# spc_me30 register map
Registers are access not given, no defined reset value unless marked. A register's access mark holds for its fields unless they carry their own. Offsets are from the block's base; lines under a group give offsets from that group; [hi:lo] are bit positions; {n}, {i} and the like mark numbered series; 'fields as' and 'values as' point back to an identical list; <NAME> marks a mode.

## Memory map
0x50090000 SPC size 0x1000 — Secure Privilege Controller.

## SPC — Secure Privilege Controller.
Base 0x50090000
0x00 CTRL 32-bit — SPC Secure Configuration Control Register.
  [0] LOCK — Write 1 to set, disables writes to security-related control registers in the SPC. Once set, the locked registers cannot be modified nor can this bit be cleared to 0 except through a reset.
0x08 RESP 32-bit — Security Violation Response Configuration Register.
  [0] VIOLCFG — This field configures the target response in case of a secuirty violation.
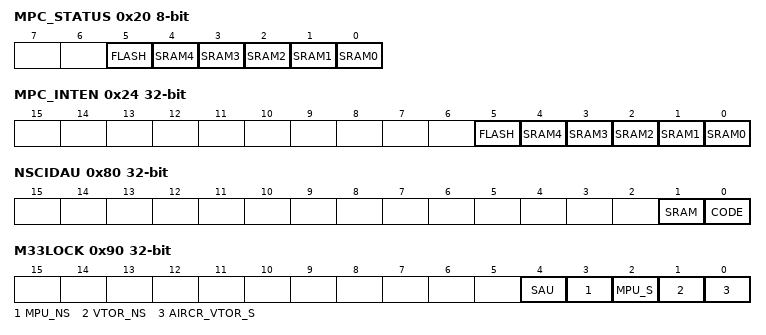
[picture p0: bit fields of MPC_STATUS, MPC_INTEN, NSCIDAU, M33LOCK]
0x20 MPC_STATUS 8-bit ro — Secure MPC Status Register.
  [5] FLASH — Interrupt status for Flash Memory Protection Controllers.
  [n] SRAM{n} (n=1..4) — Interrupt status for SRAM{n} Memory Protection Controllers.
  [0] SRAM0 — Interrupt status for SRAM 0 Memory Protection Controller.
0x24 MPC_INTEN — Secure MPC Interrupt Enable Register.
  [5] FLASH — Interrupt enable for Flash Memory Protection Controllers.
  [n] SRAM{n} (n=1..4) — Interrupt enable for SRAM{n} Memory Protection Controllers.
  [0] SRAM0 — Interrupt enable for SRAM 0 Memory Protection Controller.
0x30 PPC_STATUS ro — Secure PPC Interrupt Status Register.
  [3:0] APBPPC — Interrupt Status of APB PPC for targets on APB bus. Each bit ties to an individual PPC in the system.
0x34 PPC_INTCLR wo — Secure PPC Interrupt Clear Register.
  [3:0] APBPPC — Interrupt Clear of APB PPC for targets on the APB bus. Each bit ties to an individual PPC in the system.
0x38 PPC_INTEN — Secure PPC Interrupt Enable Register.
  [3:0] APBPPC — Interrupt Enable for APB PPC for targets on the APB bus. Each bit ties to an individual PPC in the system.
0x80 NSCIDAU — Non-Secure Callabale IDAU Configuration Register.
  [1] SRAM — Configures whether the RAM region is Non-secure Callable.
  [0] CODE — Configures whether the CODE region is Non-secure Callable.
0x90 M33LOCK — M33 Core Register Lock Configuratrion Register.
  [4] SAU — Lock Security Attribution Unit (SAU).
  [3] MPU_NS — Lock non-secure MPU registers.
  [2] MPU_S — Lock secure MPU registers.
  [1] VTOR_NS — Lock VTOR_NS register.
  [0] AIRCR_VTOR_S — Lock VTOR_S, AIRCR.PRIS, and AIRCR.BFHFNMINS.
0x120 APBSEC — APB Target Secure/Non-secure PPC Access Register.
  [31:0] PERIPH — Each bit configures the APB PPC to enforce the security access allowed for an individual peripheral.
    1=GCR (Security Access for GCR.); 2=SIR (Security Access for SIR.); 4=FCR (Security Access for FCR.); 8=WDT (Security Access for WDT.); 16=AES (Security Access for AES.); 32=AESKEYS (Security Access for AESKEYS.); 64=CRC (Security Access for CRC.); 128=GPIO0 (Security Access for GPIO0.); 0x100=TMR0 (Security Access for TMR0.); 0x200=TMR1 (Security Access for TMR1.); 0x400=TMR2 (Security Access for TMR2.); 0x800=TMR3 (Security Access for TMR3.); 0x1000=TMR4 (Security Access for TMR4.); 0x2000=TMR5 (Security Access for TMR5.); 0x4000=I3C (Security Access for I3C.); 0x8000=UART (Security Access for UART.); 0x10000=SPI (Security Access for SPI.); 0x20000=TRNG (Security Access for TRNG.); 0x40000=BTLE_DBB (Security Access for BTLE DBB.); 0x80000=BTLE_RFFE (Security Access for BTLE RFFE.); 0x100000=RSTZ (Security Access for RSTZ.); 0x200000=BOOST (Security Access for Boost Controller.); 0x400000=TRIMSIR (Security Access for TRIMSIR.); 0x1000000=RTC (Security Access for RTC.); 0x2000000=WUT0 (Security Access for WUT0.); 0x4000000=WUT1 (Security Access for WUT1.); 0x8000000=PWRSEQ (Security Access for Power Sequencer.); 0x10000000=MCR (Security Access for MCR.); 0x1F7FFFFF=ALL (Security Access for all peripherals.)
0x160 APBPRIV — APB Tartet Privileged/Non-privileged PPC Access Register.
  [31:0] PERIPH — Each bit configures the APB PPC to enforce the security access allowed for an individual peripheral.
    1=GCR (Privilege setting for GCR.); 2=SIR (Privilege setting for SIR.); 4=FCR (Privilege setting for FCR.); 8=WDT (Privilege setting for WDT.); 16=AES (Privilege setting for AES.); 32=AESKEYS (Privilege setting for AESKEYS.); 64=CRC (Privilege setting for CRC.); 128=GPIO0 (Privilege setting for GPIO0.); 0x100=TMR0 (Privilege setting for TMR0.); 0x200=TMR1 (Privilege setting for TMR1.); 0x400=TMR2 (Privilege setting for TMR2.); 0x800=TMR3 (Privilege setting for TMR3.); 0x1000=TMR4 (Privilege setting for TMR4.); 0x2000=TMR5 (Privilege setting for TMR5.); 0x4000=I3C (Privilege setting for I3C.); 0x8000=UART (Privilege setting for UART.); 0x10000=SPI (Privilege setting for SPI.); 0x20000=TRNG (Privilege setting for TRNG.); 0x40000=BTLE_DBB (Privilege setting for BTLE DBB.); 0x80000=BTLE_RFFE (Privilege setting for BTLE RFFE.); 0x100000=RSTZ (Privilege setting for RSTZ.); 0x200000=BOOST (Privilege setting for Boost Controller.); 0x400000=TRIMSIR (Privilege setting for TRIMSIR.); 0x1000000=RTC (Privilege setting for RTC.); 0x2000000=WUT0 (Privilege setting for WUT0.); 0x4000000=WUT1 (Privilege setting for WUT1.); 0x8000000=PWRSEQ (Privilege setting for Power Sequencer.); 0x10000000=MCR (Privilege setting for MCR.); 0x1F7FFFFF=ALL (Privilege setting for all peripherals.)
0x170 AHBMPRIV — AHB Privileged/Non-privileged Secure DMA Access.
  [0] DMA — Controls access of transactions coming from the Secure DMA.
0x180 GPIO0 — Secure GPIO0 Configuration Register.
  [13:0] PINS — Each bit configures a GPIO pin as secure or non-secure on GPIO Port 0. Secure GPIO pins prevent software from reading GPIO Data In pin states.
